# STM32WBA20xx register map
File version: 1.0
Registers are 32-bit, read-write, reset 0x0 unless marked. A register's access mark holds for its fields unless they carry their own. Offsets are from the block's base; lines under a group give offsets from that group; [hi:lo] are bit positions; {n}, {i} and the like mark numbered series; 'fields as' and 'values as' point back to an identical list; <NAME> marks a mode.

## Memory map
0x40000000 TIM2 — TIM
0x40003000 IWDG
0x40013800 USART1 — Universal Synchronous Asynchronous Receiver Transmitter
0x40014400 TIM16 — TIM
0x40020000 LPDMA1 — DMA Controller
0x40022000 FLASH — FLASH Registers
0x40023000 CRC — CRC calculation unit
0x40026000 RAMCFG
0x40030400 ICACHE — Instruction Cache
0x42020000 GPIOA — General Purpose I/O
0x42020400 GPIOB — General Purpose I/O
0x42020800 GPIOC — General Purpose I/O
0x42021C00 GPIOH — General Purpose I/O
0x420C0000 AES — AES hardware accelerator
0x420C0400 HASH
0x420C0800 RNG
0x420C2000 PKA
0x46000400 SYSCFG — System configuration controller
0x46002000 SPI3 — SPI
0x46002400 LPUART1 — Universal Synchronous Asynchronous Receiver Transmitter
0x46002800 I2C3 — Inter-integrated Circuit Interface
0x46004400 LPTIM1 — LPTIMER
0x46007800 RTC — Real-Time Clock
0x46007C00 TAMP — Tamper and backup registers
0x46020800 PWR — Power Control
0x46020C00 RCC — Reset and Clock Control
0x46021000 ADC4 — Analog to Digital Converter (ADC)
0x46022000 EXTI — Asynch Interrupt/Event Controller (EXTI)
0xE0044000 DBGMCU — Debug MCU

## Interrupts
2 RTC — RTC non-secure interrupt
4 TAMP — Tamper global interrupt
5 RAMCFG — RAMCFG global interrupt
6 FLASH — FLASH non-secure global interrupt
9 RCC — RCC non secure global interrupt
{n+11} EXTI{n} (EXTI) (n=0..9) — EXTI Line{n} interrupt
23 EXTI12 (EXTI) — EXTI Line12 interrupt
24 EXTI13 (EXTI) — EXTI Line13 interrupt
25 EXTI14 (EXTI) — EXTI Line14 interrupt
26 EXTI15 (EXTI) — EXTI Line15 interrupt
27 IWDG — IWDG global interrupt
{n+28} LPDMA1_Channel{n} (LPDMA1) (n=0..7) — LPDMA1 Channel {n} global interrupt
40 TIM2 — TIM2 global interrupt
43 USART1 — USART1 global interrupt
44 LPUART1 — LPUART1 global interrupt
45 LPTIM1 — LPTIM1 global interrupt
47 TIM16 — TIM16 global interrupt
49 I2C3_EV (I2C3) — I2C3 Event interrupt
50 I2C3_ER (I2C3) — I2C3 Error interrupt
52 AES — AES global interrupt
53 RNG — RNG global interrupt
55 HASH — HASH global interrupt
56 PKA — PKA global interrupt
57 SPI3 — SPI3 global interrupt
58 ICACHE — Instruction cache global interrupt
59 ADC4 — ADC4 global interrupt
63 RCC_AUDIOSYNC (RCC) — RCC audio synchronization interrupt

## IWDG
Base 0x40003000
0x00 KR — IWDG Key register
  [15:0] KEY — Key value (write only, read 0000h)
0x04 PR — IWDG Prescaler register
  [3:0] PR — PR[3:0] (Prescaler divider)
0x08 RLR — IWDG Reload register
  [11:0] RL — Watchdog counter reload value
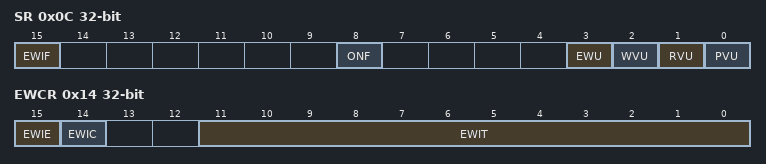
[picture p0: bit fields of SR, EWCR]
0x0C SR — IWDG Status register
  [15] EWIF — Watchdog early interrupt flag
  [8] ONF — Watchdog enable status bit
  [3] EWU — Watchdog interrupt comparator value update
  [2] WVU — Watchdog counter window value update
  [1] RVU — Watchdog counter reload value update
  [0] PVU — Watchdog prescaler value update
0x10 WINR — IWDG Window register
  [11:0] WIN — Watchdog counter window value
0x14 EWCR — IWDG Early Wakeup register
  [15] EWIE — Watchdog early wakeup comparator value
  [14] EWIC — Watchdog early wakeup comparator value
  [11:0] EWIT — Watchdog early wakeup comparator value

## CRC — CRC calculation unit
Base 0x40023000
0x00 DR — CRC Data register
  [31:0] DR — Data register bits
0x04 IDR — CRC Independent data register
  [31:0] IDR — General-purpose 32-bits data register bits
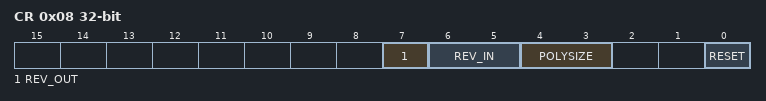
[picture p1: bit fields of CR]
0x08 CR — CRC Control register
  [7] REV_OUT — REV_OUT Reverse Output Data bits
    0=NONE (Output Data bit order not affected); 1=BIT (Output Data bit reversal done by bit)
  [6:5] REV_IN — REV_IN Reverse Input Data bits
    0=NONE (Input Data bit order not affected); 1=BYTE (Input Data bit reversal done by byte); 2=HALFWORD (Input Data bit reversal done by half-word); 3=WORD (Input Data bit reversal done by word)
  [4:3] POLYSIZE — Polynomial size bits
    0=POLYLENGTH_32B (32 bits Polynomial size); 1=POLYLENGTH_16B (16 bits Polynomial size); 2=POLYLENGTH_8B (8 bits Polynomial size); 3=POLYLENGTH_7B (7 bits Polynomial size)
  [0] RESET — RESET the CRC computation unit bit
0x10 INIT — Initial CRC value register
  [31:0] INIT — Initial CRC value bits
0x14 POL — CRC polynomial register
  [31:0] POL — Coefficients of the polynomial
